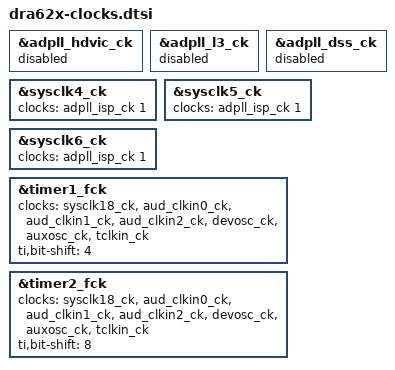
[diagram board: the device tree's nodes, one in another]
#include "dm814x-clocks.dtsi"
&adpll_hdvic_ck {
	status = "disabled";
};
&adpll_l3_ck {
	status = "disabled";
};
&adpll_dss_ck {
	status = "disabled";
};
&sysclk4_ck {
	clocks = <&adpll_isp_ck 1>;
};
&sysclk5_ck {
	clocks = <&adpll_isp_ck 1>;
};
&sysclk6_ck {
	clocks = <&adpll_isp_ck 1>;
};
&timer1_fck {
	clocks = <&sysclk18_ck &aud_clkin0_ck &aud_clkin1_ck
		  &aud_clkin2_ck &devosc_ck &auxosc_ck &tclkin_ck>;
	ti,bit-shift = <4>;
};
&timer2_fck {
	clocks = <&sysclk18_ck &aud_clkin0_ck &aud_clkin1_ck
		  &aud_clkin2_ck &devosc_ck &auxosc_ck &tclkin_ck>;
	ti,bit-shift = <8>;
};
